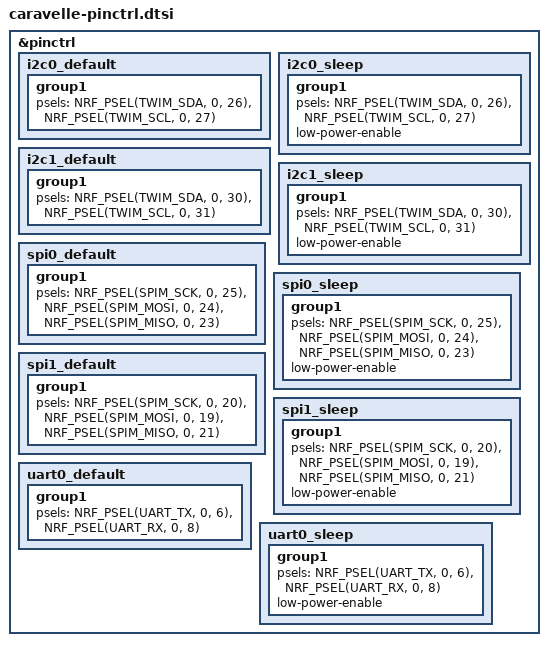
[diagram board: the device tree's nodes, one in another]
// TODO 使用していないので削除するか確認すること

&pinctrl {
	i2c0_default: i2c0_default {
		group1 {
			psels = <NRF_PSEL(TWIM_SDA, 0, 26)>,
				<NRF_PSEL(TWIM_SCL, 0, 27)>;
		};
	};

	i2c0_sleep: i2c0_sleep {
		group1 {
			psels = <NRF_PSEL(TWIM_SDA, 0, 26)>,
				<NRF_PSEL(TWIM_SCL, 0, 27)>;
			low-power-enable;
		};
	};

	i2c1_default: i2c1_default {
		group1 {
			psels = <NRF_PSEL(TWIM_SDA, 0, 30)>,
				<NRF_PSEL(TWIM_SCL, 0, 31)>;
		};
	};

	i2c1_sleep: i2c1_sleep {
		group1 {
			psels = <NRF_PSEL(TWIM_SDA, 0, 30)>,
				<NRF_PSEL(TWIM_SCL, 0, 31)>;
			low-power-enable;
		};
	};

	spi0_default: spi0_default {
		group1 {
			psels = <NRF_PSEL(SPIM_SCK, 0, 25)>,
				<NRF_PSEL(SPIM_MOSI, 0, 24)>,
				<NRF_PSEL(SPIM_MISO, 0, 23)>;
		};
	};

	spi0_sleep: spi0_sleep {
		group1 {
			psels = <NRF_PSEL(SPIM_SCK, 0, 25)>,
				<NRF_PSEL(SPIM_MOSI, 0, 24)>,
				<NRF_PSEL(SPIM_MISO, 0, 23)>;
			low-power-enable;
		};
	};

	spi1_default: spi1_default {
		group1 {
			psels = <NRF_PSEL(SPIM_SCK, 0, 20)>,
				<NRF_PSEL(SPIM_MOSI, 0, 19)>,
				<NRF_PSEL(SPIM_MISO, 0, 21)>;
		};
	};

	spi1_sleep: spi1_sleep {
		group1 {
			psels = <NRF_PSEL(SPIM_SCK, 0, 20)>,
				<NRF_PSEL(SPIM_MOSI, 0, 19)>,
				<NRF_PSEL(SPIM_MISO, 0, 21)>;
			low-power-enable;
		};
	};

	uart0_default: uart0_default {
		group1 {
			psels = <NRF_PSEL(UART_TX, 0, 6)>,
				<NRF_PSEL(UART_RX, 0, 8)>;
		};
	};

	uart0_sleep: uart0_sleep {
		group1 {
			psels = <NRF_PSEL(UART_TX, 0, 6)>,
				<NRF_PSEL(UART_RX, 0, 8)>;
			low-power-enable;
		};
	};
};
